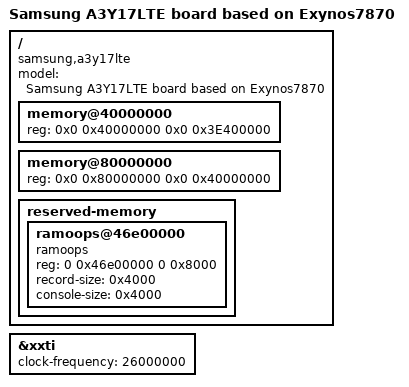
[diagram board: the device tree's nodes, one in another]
/*
 * Copyright (c) 2016 Samsung Electronics Co., Ltd.
 *		http://www.samsung.com
 *
 * This program is free software; you can redistribute it and/or modify
 * it under the terms of the GNU General Public License version 2 as
 * published by the Free Software Foundation.
*/

#include "exynos7870.dtsi"

/ {
	model = "Samsung A3Y17LTE board based on Exynos7870";
	compatible = "samsung,a3y17lte", "samsung,exynos7870";

	memory@40000000 {
		device_type = "memory";
		reg = <0x0 0x40000000 0x0 0x3E400000>;
	};

	memory@80000000 {
		device_type = "memory";
		reg = <0x0 0x80000000 0x0 0x40000000>;
	};

	reserved-memory {
		#address-cells = <2>;
		#size-cells = <2>;
		ranges;

		ramoops@46e00000 {
			compatible = "ramoops";
			reg = <0 0x46e00000 0 0x8000>;
			record-size = <0x4000>;
			console-size = <0x4000>;
		};
	};
};

&xxti {
	clock-frequency = <26000000>;
};
